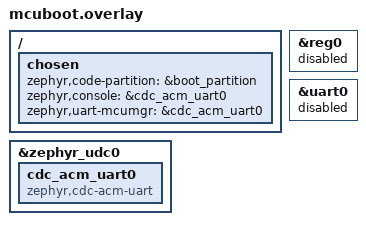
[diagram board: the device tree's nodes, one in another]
/*
 * MCUboot 용 DTS 오버레이. `sysbuild/mcuboot.overlay` 파일이어야 하고
 * `sysbuild/mcuboot/` 디렉터리를 만들면 안 된다 (sysbuild 가 그 디렉터리를
 * MCUboot 의 설정 디렉터리 전체로 취급 — 선반 docs/build-and-flash.md §3.2).
 *
 * 이 파일은 MCUboot 자신의 app.overlay 를 "대체"하므로 code-partition chosen
 * 이 반드시 있어야 한다. 빠지면 MCUboot 이 slot0 에 링크되어 앱을 구울 때
 * 부트로더가 덮여 보드가 영영 부팅하지 않는다.
 */

#include "../partitions.dtsi"

/ {
	chosen {
		zephyr,code-partition = &boot_partition;
		zephyr,console = &cdc_acm_uart0;
		zephyr,uart-mcumgr = &cdc_acm_uart0;
	};
};

/* 애플리케이션과 동일: normal-voltage 모드, REG0 DC/DC 금지 */
&reg0 {
	status = "disabled";
};

&uart0 {
	status = "disabled";
};

&zephyr_udc0 {
	cdc_acm_uart0: cdc_acm_uart0 {
		compatible = "zephyr,cdc-acm-uart";
	};
};
